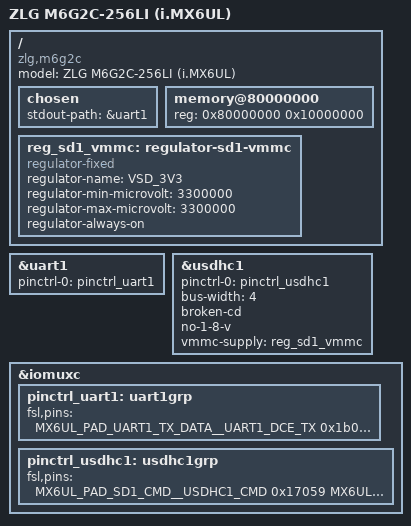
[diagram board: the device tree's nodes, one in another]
// SPDX-License-Identifier: (GPL-2.0+ OR MIT)
/*
 * U-Boot device tree for the ZLG M6G2C core module (i.MX6UL, 256 MiB).
 * Only what the boot loader needs: the debug UART and the SD card.
 * The full hardware description lives in the kernel DTS.
 */

/dts-v1/;

#include "imx6ul.dtsi"

/ {
	model = "ZLG M6G2C-256LI (i.MX6UL)";
	compatible = "zlg,m6g2c", "fsl,imx6ul";

	chosen {
		stdout-path = &uart1;
	};

	memory@80000000 {
		device_type = "memory";
		reg = <0x80000000 0x10000000>;
	};

	reg_sd1_vmmc: regulator-sd1-vmmc {
		compatible = "regulator-fixed";
		regulator-name = "VSD_3V3";
		regulator-min-microvolt = <3300000>;
		regulator-max-microvolt = <3300000>;
		regulator-always-on;
	};
};

&uart1 {
	pinctrl-names = "default";
	pinctrl-0 = <&pinctrl_uart1>;
	status = "okay";
};

&usdhc1 {
	pinctrl-names = "default";
	pinctrl-0 = <&pinctrl_usdhc1>;
	bus-width = <4>;
	broken-cd;		/* card-detect wiring is carrier specific; poll */
	no-1-8-v;		/* no 1.8 V I/O switching on the carrier */
	vmmc-supply = <&reg_sd1_vmmc>;
	status = "okay";
};

&iomuxc {
	pinctrl_uart1: uart1grp {
		fsl,pins = <
			MX6UL_PAD_UART1_TX_DATA__UART1_DCE_TX	0x1b0b1
			MX6UL_PAD_UART1_RX_DATA__UART1_DCE_RX	0x1b0b1
		>;
	};

	pinctrl_usdhc1: usdhc1grp {
		fsl,pins = <
			MX6UL_PAD_SD1_CMD__USDHC1_CMD		0x17059
			MX6UL_PAD_SD1_CLK__USDHC1_CLK		0x10059
			MX6UL_PAD_SD1_DATA0__USDHC1_DATA0	0x17059
			MX6UL_PAD_SD1_DATA1__USDHC1_DATA1	0x17059
			MX6UL_PAD_SD1_DATA2__USDHC1_DATA2	0x17059
			MX6UL_PAD_SD1_DATA3__USDHC1_DATA3	0x17059
		>;
	};
};
